# QN908X register map
Vendor: nxp.com; File version: 1.0
CPU: CM4 r0p1, little endian, MPU, FPU, VTOR, 3 interrupt priority bits
Registers are 32-bit, read-write, reset 0x0 unless marked. A register's access mark holds for its fields unless they carry their own. Offsets are from the block's base; lines under a group give offsets from that group; [hi:lo] are bit positions; {n}, {i} and the like mark numbered series; 'fields as' and 'values as' point back to an identical list; <NAME> marks a mode.

## Memory map
0x40000000 SYSCON size 0x894
0x40001000 WDT size 0x48 — wdog
0x40002000 CTIMER0 size 0x78 — timer
0x40003000 CTIMER1 size 0x78 — timer
0x40004000 CTIMER2 size 0x78 — timer
0x40005000 CTIMER3 size 0x78 — timer
0x40006000 PINT size 0x34 — QN908X Pin interrupt and pattern match (PINT)
0x40006200 INPUTMUX size 0x810 — dmamux
0x40007000 ADC size 0x100
0x40007400 DAC size 0x2C
0x40007800 CS size 0x24 — tsc
0x40007C00 RNG size 0x14
0x40009000 QDEC0 size 0x28 — qdec
0x40009800 QDEC1 size 0x28 — qdec
0x4000A000 CHRG size 0x14
0x4000B000 RTC size 0x30
0x4000C000 AGC size 0x1C
0x4000D000 PROP size 0xC
0x4000E000 BLEDP size 0xA4
0x4000F000 CALIB size 0x83C
0x40080000 SPIFI0 size 0x20 — spifi
0x40081000 FLASH size 0xB0
0x40082000 DMA0 size 0x53C — LPC5411x DMA controller
0x40083000 FLEXCOMM0 size 0x1000 — flexcomm
0x40083000 USART0 size 0x1000 — usart
0x40084000 USB0 size 0x38 — usb
0x40085000 SCT0 size 0x800 — LPC5411x SCTimer/PWM (SCT)
0x40086000 FLEXCOMM1 size 0x1000 — flexcomm
0x40086000 I2C0 size 0x1000 — i2c
0x40086000 USART1 size 0x1000 — usart
0x40087000 FLEXCOMM2 size 0x1000 — flexcomm
0x40087000 I2C1 size 0x1000 — i2c
0x40087000 SPI0 size 0x1000 — spi
0x40088000 FSP size 0x1A0
0x4008C000 GPIOA size 0x3C — gpio
0x4008D000 GPIOB size 0x3C — gpio
0x4008E000 CRC_ENGINE size 0xC — crc
0x4008F000 FLEXCOMM3 size 0x1000 — flexcomm
0x4008F000 SPI1 size 0x1000 — spi

## WDT — wdog
Base 0x40001000
0x00 LOAD reset 0xFFFF — watch dog counter start value register
  [31:0] LOAD — Contain the value from which the counter is to decrement. When this register is written to the count is immediately restarted from the new value. The minimum valid value is 1.
0x04 VALUE reset 0x1FFFFFFF — watch dog counter value register
  [31:0] VALUE — The current value of the decrementing counter.
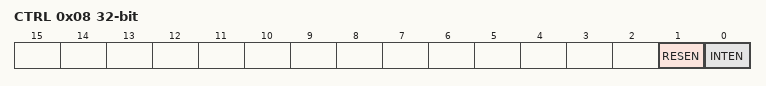
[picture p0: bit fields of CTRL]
0x08 CTRL — watch dog control register
  [1] RESEN — Enable watchdog reset output WDOGRES. Acts as a mask for the reset output. Set HIGH to enablethe reset and LOW to disable the reset.
  [0] INTEN — Enable the interrupt event WDOGINT. Set HIGH to enable the counter and the interrupt and set
0x0C INT_CLR — interrupt clear register
  [0] INTCLR — A write of any value to the Register clears the watchdog interrupt and reloads the counter from the value in WDOGLOAD.
0x10 INT_RAW ro — raw interrupt status register
  [0] RAWINTSTAT — Raw interrupt status from the counter
0x14 MIS — interrupt mask register
  [0] MASKINTSTAT — Enabled interrupt status from the counter
0x20 LOCK — watch dog lock register
  [31:0] LOCK_31_0 — Writing 0x1ACCE551to this register enables write access to all other registers.
0x40 ITCR — integrated test control register
  [0] INTEGTESTEN — When set HIGH places the watchdog into integration test mode
0x44 ITOP — integrated test output set register
  [1:0] INTEGTESTOUTSET — write 1 to bit 1 to set user interrupt, write 1 to bit 0 to set user reset

## INPUTMUX — dmamux
Base 0x40006200
{0x0+4i} PINTSEL[{i}] (i=0..7) — Pin interrupt select register
  [7:0] INTPIN — Pin number select for pin interrupt or pattern match engine input. (PIO0_0 to PIO1_31 correspond to numbers 0 to 63).
{0x200+4i} DMA_ITRIG_INMUX[{i}] (i=0..21) reset 0x1F — Trigger select register for DMA channel
  [4:0] INP — Trigger input number (decimal value) for DMA channel n (n = 0 to 21). 0 = ADC0 Sequence A interrupt 1 = ADC0 Sequence B interrupt 2 = SCT0 DMA request 0 3 = SCT0 DMA request 1 4 = Timer CT32B0 Match 0 5 = Timer CT32B0 Match 1 6 = Timer CT32B1 Match 0 7 = Timer CT32B2 Match 0 8 = Timer CT32B2 Match 1 9 = Timer CT32B3 Match 0 10 = Timer CT32B4 Match 0 11 = Timer CT32B4 Match 1 12 = Pin interrupt 0 13 = Pin interrupt 1 14 = Pin interrupt 2 15 = Pin interrupt 3 16 = DMA output trigger mux 0 17 = DMA output trigger mux 1 18 = DMA output trigger mux 2 19 = DMA output trigger mux 3
{0x800+4i} DMA_OTRIG_INMUX[{i}] (i=0..3) reset 0x1F — DMA output trigger selection to become DMA trigger
  [4:0] INP — DMA trigger output number (decimal value) for DMA channel n (n = 0 to 19).
